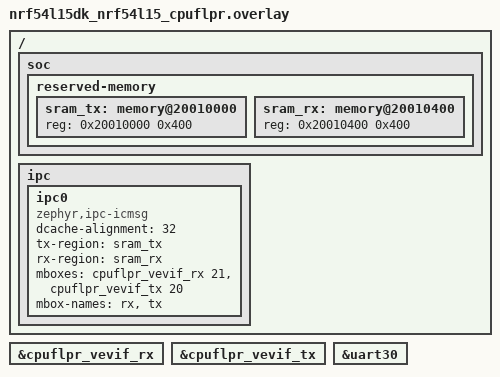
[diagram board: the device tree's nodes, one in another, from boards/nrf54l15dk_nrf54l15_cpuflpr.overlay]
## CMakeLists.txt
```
#
# Copyright (c) 2024 Nordic Semiconductor ASA
#
# SPDX-License-Identifier: LicenseRef-Nordic-5-Clause
#

cmake_minimum_required(VERSION 3.20.0)

find_package(Zephyr REQUIRED HINTS $ENV{ZEPHYR_BASE})
project(remote_icmsg)

target_sources(app PRIVATE src/main.c)

# CMSIS FFT Q15 Simplified
target_sources(app PRIVATE
    src/rfft_init_q15.c
    src/rfft_q15.c
    src/cfft_q15.c
    src/cfft_radix4_q15.c
    src/bit_reversal.c
    src/twiddle_tables.c
    src/fft_utils.c
)

# Ensure twiddle factor tables are placed in Flash (read-only)
# This is handled automatically by the linker for const data

# Dead code elimination
target_link_options(app PRIVATE
    -Wl,--gc-sections
)
```

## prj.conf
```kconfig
# Copyright (c) 2024 Nordic Semiconductor ASA
# SPDX-License-Identifier: LicenseRef-Nordic-5-Clause

CONFIG_PRINTK=y

CONFIG_LOG=y
CONFIG_LOG_PROCESS_THREAD_PRIORITY=-15
CONFIG_LOG_PROCESS_THREAD_CUSTOM_PRIORITY=y

CONFIG_HEAP_MEM_POOL_SIZE=1024

# Disable IPC Service - using simple ping-pong buffer instead
# CONFIG_IPC_SERVICE=y
# CONFIG_IPC_SERVICE_LOG_LEVEL_INF=y

# BELLBOARD (MBOX) for inter-core interrupts
CONFIG_MBOX=y
CONFIG_PM=n

# Enable XIP mode - execute code directly from Flash
CONFIG_XIP=y
```

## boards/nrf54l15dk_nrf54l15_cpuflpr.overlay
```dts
/*
 * FLPR IPC configuration for XIP memory layout
 * Shared memory region: 160KB (0x20010000-0x20038000)
 * TX/RX swapped from M33 perspective for bidirectional communication
 */

/ {
	soc {
		reserved-memory {
			#address-cells = <1>;
			#size-cells = <1>;

			// TX buffer: 1KB at 0x20010000 (M33's RX)
			sram_tx: memory@20010000 {
				reg = <0x20010000 0x400>;  // 1KB
			};

			// RX buffer: 1KB at 0x20010400 (M33's TX)
			sram_rx: memory@20010400 {
				reg = <0x20010400 0x400>;  // 1KB
			};
		};
	};

	ipc {
		ipc0: ipc0 {
			compatible = "zephyr,ipc-icmsg";
			dcache-alignment = <32>;
			tx-region = <&sram_tx>;
			rx-region = <&sram_rx>;
			mboxes = <&cpuflpr_vevif_rx 21>, <&cpuflpr_vevif_tx 20>;
			mbox-names = "rx", "tx";
			status = "okay";
		};
	};
};

&cpuflpr_vevif_rx {
	status = "okay";
};

&cpuflpr_vevif_tx {
	status = "okay";
};

&uart30 {
	/delete-property/ hw-flow-control;
};
```

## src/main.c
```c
/*
 * Copyright (c) 2025 Nordic Semiconductor ASA
 *
 * SPDX-License-Identifier: LicenseRef-Nordic-5-Clause
 *
 * Simple BELLBOARD Interrupt Test - FLPR Side
 * 
 * This test validates basic BELLBOARD interrupt functionality:
 * - FLPR sends interrupts to M33
 * - FLPR receives interrupts from M33
 * - Shared memory communication works
 */

#include <zephyr/kernel.h>
#include <zephyr/device.h>
#include <zephyr/drivers/mbox.h>
#include <zephyr/logging/log.h>
#include "ipc_pingpong.h"

LOG_MODULE_REGISTER(flpr_bellboard_test, LOG_LEVEL_INF);

/* Control block structure in shared memory */
struct control_block {
	volatile uint32_t flpr_counter;
	volatile uint32_t m33_counter;
	volatile uint32_t flpr_to_m33_count;
	volatile uint32_t m33_to_flpr_count;
};

static struct control_block *ctrl = (struct control_block *)CONTROL_BLOCK_ADDR;

/* Track last used buffer for round-robin selection */
static uint8_t last_buffer_used = 1;  /* Start with 1 so first acquisition tries buffer 0 */

/* MBOX device for BELLBOARD */
static const struct device *mbox_dev;
static const struct device *mbox_tx_dev;

/**
 * Notify M33 core via VEVIF interrupt
 * 
 * This function:
 * - Executes a memory barrier to ensure all writes are visible
 * - Triggers a VEVIF interrupt to M33 (channel 20)
 * - Handles errors from mbox_send
 * 
 * Requirements: 4.4, 7.1
 * 
 * @return BUFFER_OK on success, BUFFER_ERR_INVALID on failure
 */
static int vevif_notify_m33(void)
{
	int ret;
	
	/* Execute memory barrier before VEVIF trigger to ensure data visibility */
	MEMORY_BARRIER_FULL();
	
	/* Trigger VEVIF interrupt to M33 */
	ret = mbox_send_dt(&(struct mbox_dt_spec){
		.dev = mbox_tx_dev,
		.channel_id = 20
	}, NULL);
	
	if (ret < 0) {
		LOG_ERR("Failed to notify M33: %d", ret);
		return BUFFER_ERR_INVALID;
	}
	
	return BUFFER_OK;
}

/**
 * Acquire next available buffer for writing (FLPR write path)
 * 
 * This function:
 * - Searches for next IDLE buffer in round-robin order
 * - Uses atomic CAS to transition IDLE → WRITING
 * - Implements timeout using k_uptime_get() and polling
 * - Detects overrun when both buffers are not IDLE
 * - Increments overrun counter on overrun detection
 * - Returns buffer handle with pointer to data region
 * 
 * Requirements: 3.1, 3.2, 3.3, 6.1, 6.2, 6.3
 * 
 * @param handle Pointer to buffer_handle_t to populate
 * @param timeout_ms Timeout in milliseconds (0 = non-blocking)
 * @return BUFFER_OK on success, BUFFER_ERR_TIMEOUT on timeout, BUFFER_ERR_INVALID on invalid params
 */
int buffer_acquire_for_write(buffer_handle_t *handle, uint32_t timeout_ms)
{
	uint64_t start_time;
	uint64_t current_time;
	bool overrun_detected = false;
	
	/* Validate parameters */
	if (handle == NULL) {
		LOG_ERR("Invalid handle parameter");
		return BUFFER_ERR_INVALID;
	}
	
	/* Record start time for timeout */
	start_time = k_uptime_get();
	
	/* Try to acquire a buffer with timeout */
	while (1) {
		/* Try next buffer in round-robin order */
		uint8_t buffer_id = (last_buffer_used + 1) % 2;
		buffer_state_t current_state = buffer_get_state(buffer_id);
		
		if (current_state == BUFFER_STATE_IDLE) {
			/* Try to atomically transition IDLE → WRITING */
			if (atomic_cas_state(&CONTROL_BLOCK->buffer_states[buffer_id],
			                     BUFFER_STATE_IDLE,
			                     BUFFER_STATE_WRITING)) {
				/* Successfully acquired buffer */
				handle->id = buffer_id;
				handle->data = (void *)(buffer_id == 0 ? BUFFER_0_ADDR : BUFFER_1_ADDR);
				handle->size = BUFFER_SIZE;
				handle->state = &CONTROL_BLOCK->buffer_states[buffer_id];
				
				/* Update last used buffer for round-robin */
				last_buffer_used = buffer_id;
				
				LOG_DBG("Acquired buffer %d for writing", buffer_id);
				return BUFFER_OK;
			}
			/* CAS failed, another core may have acquired it, continue trying */
		}
		
		/* Check if both buffers are not IDLE (overrun condition) */
		buffer_state_t state0 = buffer_get_state(0);
		buffer_state_t state1 = buffer_get_state(1);
		
		if (state0 != BUFFER_STATE_IDLE && state1 != BUFFER_STATE_IDLE) {
			/* Overrun detected - both buffers are occupied */
			if (!overrun_detected) {
				/* Increment overrun counter only once per acquisition attempt */
				atomic_inc((atomic_t *)&CONTROL_BLOCK->overrun_count);
				overrun_detected = true;
				LOG_WRN("Buffer overrun detected (count: %d)", CONTROL_BLOCK->overrun_count);
			}
		}
		
		/* Check timeout */
		current_time = k_uptime_get();
		if ((current_time - start_time) >= timeout_ms) {
			LOG_WRN("Buffer acquisition timeout after %u ms", timeout_ms);
			atomic_inc((atomic_t *)&CONTROL_BLOCK->timeout_count);
			return BUFFER_ERR_TIMEOUT;
		}
		
		/* Small delay before retry to avoid busy-waiting */
		k_usleep(100);
	}
	
	/* Should never reach here */
	return BUFFER_ERR_INVALID;
}

/**
 * Commit written buffer and notify M33 (FLPR write path)
 * 
 * This function:
 * - Uses atomic CAS to transition WRITING → READY
 * - Executes memory barrier before notification
 * - Calls vevif_notify_m33() to trigger interrupt
 * - Increments write counter for the buffer
 * - Records timestamp using k_uptime_get()
 * 
 * Requirements: 3.4, 4.1, 7.1, 10.1, 10.2
 * 
 * @param handle Pointer to buffer_handle_t for the buffer to commit
 * @return BUFFER_OK on success, BUFFER_ERR_INVALID on invalid params, BUFFER_ERR_STATE on wrong state
 */
int buffer_commit(buffer_handle_t *handle)
{
	int ret;
	
	/* Validate parameters */
	if (handle == NULL) {
		LOG_ERR("Invalid handle parameter");
		return BUFFER_ERR_INVALID;
	}
	
	if (handle->id > 1) {
		LOG_ERR("Invalid buffer ID: %d", handle->id);
		return BUFFER_ERR_INVALID;
	}
	
	/* Try to atomically transition WRITING → READY */
	if (!atomic_cas_state(&CONTROL_BLOCK->buffer_states[handle->id],
	                      BUFFER_STATE_WRITING,
	                      BUFFER_STATE_READY)) {
		/* State transition failed - buffer is not in WRITING state */
		buffer_state_t current_state = buffer_get_state(handle->id);
		LOG_ERR("Buffer %d commit failed: expected WRITING, got %d", 
		        handle->id, current_state);
		return BUFFER_ERR_STATE;
	}
	
	/* Increment write counter for this buffer */
	atomic_inc((atomic_t *)&CONTROL_BLOCK->write_count[handle->id]);
	
	/* Record timestamp */
	uint64_t timestamp = k_uptime_get();
	CONTROL_BLOCK->last_write_ts[handle->id] = timestamp;
	
	/* Execute memory barrier before notification to ensure data visibility */
	MEMORY_BARRIER_FULL();
	
	/* Notify M33 that buffer is ready */
	ret = vevif_notify_m33();
	if (ret != BUFFER_OK) {
		LOG_ERR("Failed to notify M33 after commit: %d", ret);
		/* Note: Buffer is already in READY state, so M33 can still process it
		 * even if notification failed. This is a non-fatal error. */
	}
	
	LOG_DBG("Committed buffer %d (write count: %d, timestamp: %llu)",
	        handle->id, CONTROL_BLOCK->write_count[handle->id], timestamp);
	
	return BUFFER_OK;
}

/* Callback for BELLBOARD interrupt from M33 */
static void mbox_callback(const struct device *dev, uint32_t channel,
			  void *user_data, struct mbox_msg *msg)
{
	ARG_UNUSED(dev);
	ARG_UNUSED(user_data);
	ARG_UNUSED(msg);

	/* Increment interrupt counter */
	ctrl->m33_to_flpr_count++;

	LOG_INF("FLPR: Received interrupt #%d from M33 (M33 counter: %d)",
		ctrl->m33_to_flpr_count, ctrl->m33_counter);
}

int main(void)
{
	int ret;

	LOG_INF("=== FLPR VEVIF Interrupt Test ===");
	LOG_INF("Shared memory base: 0x%08X", (uint32_t)SHARED_MEM_BASE);
	LOG_INF("Control block: 0x%08X", (uint32_t)CONTROL_BLOCK_ADDR);

	/* Get MBOX device (VEVIF RX/TX) */
	mbox_dev = DEVICE_DT_GET(DT_NODELABEL(cpuflpr_vevif_rx));
	if (!device_is_ready(mbox_dev)) {
		LOG_ERR("MBOX RX device not ready");
		return -ENODEV;
	}

	LOG_INF("MBOX RX device ready");

	/* Get TX device */
	mbox_tx_dev = DEVICE_DT_GET(DT_NODELABEL(cpuflpr_vevif_tx));
	if (!device_is_ready(mbox_tx_dev)) {
		LOG_ERR("MBOX TX device not ready");
		return -ENODEV;
	}

	LOG_INF("MBOX TX device ready");

	/* Configure RX channel (receive from M33) - Channel 21 */
	ret = mbox_set_enabled_dt(&(struct mbox_dt_spec){
		.dev = mbox_dev,
		.channel_id = 21
	}, true);
	if (ret < 0) {
		LOG_ERR("Failed to enable RX channel: %d", ret);
		return ret;
	}

	/* Register callback for interrupts from M33 */
	ret = mbox_register_callback_dt(&(struct mbox_dt_spec){
		.dev = mbox_dev,
		.channel_id = 21
	}, mbox_callback, NULL);
	if (ret < 0) {
		LOG_ERR("Failed to register callback: %d", ret);
		return ret;
	}

	LOG_INF("RX channel configured (Channel 21: M33 -> FLPR)");
	LOG_INF("TX channel configured (Channel 20: FLPR -> M33)");
	LOG_INF("Starting ping-pong buffer test loop...");

	/* Statistics tracking */
	uint32_t iteration = 0;
	uint32_t last_stats_time = k_uptime_get_32();

	/* Main loop: acquire buffer, write data, commit, repeat */
	while (1) {
		buffer_handle_t buf;
		
		/* Acquire next available buffer for writing (1 second timeout) */
		ret = buffer_acquire_for_write(&buf, 1000);
		
		if (ret == BUFFER_ERR_TIMEOUT) {
			LOG_ERR("Failed to acquire buffer: timeout");
			/* Handle timeout - continue trying */
			k_msleep(100);
			continue;
		} else if (ret != BUFFER_OK) {
			LOG_ERR("Failed to acquire buffer: %d", ret);
			/* Handle other errors */
			k_msleep(100);
			continue;
		}
		
		/* Successfully acquired buffer - write test data pattern */
		uint32_t *data = (uint32_t *)buf.data;
		uint32_t pattern_base = iteration;
		
		/* Fill buffer with test pattern: incrementing values based on iteration */
		for (size_t i = 0; i < (buf.size / sizeof(uint32_t)); i++) {
			data[i] = pattern_base + i;
		}
		
		LOG_DBG("FLPR: Wrote test pattern to buffer %d (base: 0x%08X)", 
		        buf.id, pattern_base);
		
		/* Commit buffer and notify M33 */
		ret = buffer_commit(&buf);
		
		if (ret != BUFFER_OK) {
			LOG_ERR("Failed to commit buffer %d: %d", buf.id, ret);
			/* Buffer is in inconsistent state - this is a critical error */
			/* In production, might want to reset the buffer state */
		} else {
			LOG_INF("FLPR: Committed buffer %d (iteration %u)", buf.id, iteration);
		}
		
		/* Increment iteration counter */
		iteration++;
		
		/* Log statistics periodically (every 5 seconds) */
		uint32_t current_time = k_uptime_get_32();
		if ((current_time - last_stats_time) >= 5000) {
			LOG_INF("=== FLPR Statistics ===");
			LOG_INF("  Iterations: %u", iteration);
			LOG_INF("  Buffer 0 writes: %u", CONTROL_BLOCK->write_count[0]);
			LOG_INF("  Buffer 1 writes: %u", CONTROL_BLOCK->write_count[1]);
			LOG_INF("  Overruns: %u", CONTROL_BLOCK->overrun_count);
			LOG_INF("  Timeouts: %u", CONTROL_BLOCK->timeout_count);
			LOG_INF("  Legacy FLPR->M33: %u, M33->FLPR: %u",
			        ctrl->flpr_to_m33_count, ctrl->m33_to_flpr_count);
			
			last_stats_time = current_time;
		}
		
		/* Small delay between writes to simulate realistic data production rate */
		k_msleep(500);
	}

	return 0;
}
```

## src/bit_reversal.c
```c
/* ----------------------------------------------------------------------
 * Project:      CMSIS DSP Library - Simplified Q15 FFT
 * Title:        bit_reversal.c
 * Description:  Bit reversal functions for FFT
 *
 * Target Processor: ARM Cortex-M33
 * -------------------------------------------------------------------- */
/*
 * Copyright (C) 2010-2021 ARM Limited or its affiliates. All rights reserved.
 *
 * SPDX-License-Identifier: Apache-2.0
 */

#include "rfft_q15_simplified.h"

/**
 * @brief In-place Q15 bit reversal function.
 * @param[in,out] pSrc        points to in-place Q15 data buffer
 * @param[in]     bitRevLen   bit reversal table length
 * @param[in]     pBitRevTable points to bit reversal table
 */
void arm_bitreversal_16(
        uint16_t * pSrc,
  const uint16_t bitRevLen,
  const uint16_t * pBitRevTable)
{
    uint16_t a, b, tmp;
    uint32_t i;

    for (i = 0; i < bitRevLen; )
    {
        a = pBitRevTable[i    ] >> 2;
        b = pBitRevTable[i + 1] >> 2;

        /* Swap real parts */
        tmp = pSrc[a];
        pSrc[a] = pSrc[b];
        pSrc[b] = tmp;

        /* Swap imaginary parts */
        tmp = pSrc[a+1];
        pSrc[a+1] = pSrc[b+1];
        pSrc[b+1] = tmp;

        i += 2;
    }
}
```

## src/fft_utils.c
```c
/* ----------------------------------------------------------------------
 * Project:      FFT Utility Functions
 * Title:        fft_utils.c
 * Description:  High-level FFT utility functions implementation
 *
 * Target Processor: nRF54L15 FLPR (RISC-V)
 * -------------------------------------------------------------------- */

#include "fft_utils.h"
#include <string.h>

/* Static buffers for FFT processing */
#ifdef ENABLE_FFT_8K
static q15_t fft_input_buffer[8192];   /* Max FFT size: 8192 */
static q15_t fft_output_buffer[16384]; /* 2 * max FFT size for complex output */
#else
static q15_t fft_input_buffer[4096];   /* Max FFT size: 4096 */
static q15_t fft_output_buffer[8192];  /* 2 * max FFT size for complex output */
#endif

/* Structure for bin sorting */
typedef struct {
    uint16_t bin_index;
    uint32_t magnitude_squared;
} bin_magnitude_t;

/**
 * @brief Find the top N frequency bins with highest magnitude from FFT
 */
rfft_status_t find_fft_top_bins(
    const q15_t *input_signal,
    uint16_t input_length,
    uint16_t fft_size,
    uint16_t *output_bin_indices,
    uint16_t num_top_bins
)
{
    /* Input validation */
    if (input_signal == NULL || output_bin_indices == NULL) {
        return RFFT_ERROR_NULL_POINTER;
    }
    
    if (input_length != fft_size) {
        return RFFT_ERROR_INVALID_SIZE;
    }
    
    if (fft_size != 4096 && fft_size != 8192) {
        return RFFT_ERROR_INVALID_SIZE;
    }
    
#ifndef ENABLE_FFT_8K
    if (fft_size == 8192) {
        return RFFT_ERROR_INVALID_SIZE;  /* 8192 not enabled */
    }
#endif
    
    if (num_top_bins == 0 || num_top_bins > (fft_size / 2)) {
        return RFFT_ERROR_INVALID_SIZE;
    }
    
    /* Initialize RFFT instance */
    arm_rfft_instance_q15 rfft_instance;
    rfft_status_t status;
    
    if (fft_size == 4096) {
        status = rfft_q15_init_4096(&rfft_instance);
    } 
#ifdef ENABLE_FFT_8K
    else {
        status = rfft_q15_init_8192(&rfft_instance);
    }
#else
    else {
        return RFFT_ERROR_INVALID_SIZE;
    }
#endif
    
    if (status != RFFT_SUCCESS) {
        return status;
    }
    
    /* Copy input to working buffer */
    memcpy(fft_input_buffer, input_signal, fft_size * sizeof(q15_t));
    
    /* Perform RFFT */
    arm_rfft_q15(&rfft_instance, fft_input_buffer, fft_output_buffer);
    
    /* Allocate array for top bins (on stack) */
    bin_magnitude_t top_bins[num_top_bins];
    
    /* Initialize top_bins array */
    for (uint16_t i = 0; i < num_top_bins; i++) {
        top_bins[i].bin_index = 0;
        top_bins[i].magnitude_squared = 0;
    }
    
    /* Calculate magnitude² for all bins and find top N */
    /* Note: Skip DC bin (bin 0) */
    uint16_t num_bins = fft_size / 2 + 1;
    
    for (uint16_t bin = 1; bin < num_bins; bin++) {
        /* Get real and imaginary parts (13.3 format for 4096, 14.2 for 8192) */
        int16_t real = fft_output_buffer[bin * 2];
        int16_t imag = fft_output_buffer[bin * 2 + 1];
        
        /* Calculate magnitude² (using raw values to avoid overflow) */
        uint32_t mag_sq = (uint32_t)((int32_t)real * real + (int32_t)imag * imag);
        
        /* Check if this bin should be in top N */
        for (uint16_t i = 0; i < num_top_bins; i++) {
            if (mag_sq > top_bins[i].magnitude_squared) {
                /* Insert at position i, shift others down */
                for (uint16_t j = num_top_bins - 1; j > i; j--) {
                    top_bins[j] = top_bins[j - 1];
                }
                top_bins[i].bin_index = bin;
                top_bins[i].magnitude_squared = mag_sq;
                break;
            }
        }
    }
    
    /* Copy bin indices to output array */
    for (uint16_t i = 0; i < num_top_bins; i++) {
        output_bin_indices[i] = top_bins[i].bin_index;
    }
    
    return RFFT_SUCCESS;
}
```

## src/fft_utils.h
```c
/* ----------------------------------------------------------------------
 * Project:      FFT Utility Functions
 * Title:        fft_utils.h
 * Description:  High-level FFT utility functions for signal processing
 *
 * Target Processor: nRF54L15 FLPR (RISC-V)
 * -------------------------------------------------------------------- */

#ifndef FFT_UTILS_H
#define FFT_UTILS_H

#include "rfft_q15_simplified.h"

#ifdef __cplusplus
extern "C" {
#endif

/**
 * @brief Find the top N frequency bins with highest magnitude from FFT
 * 
 * @param[in]  input_signal      Pointer to input signal buffer (Q15 format)
 * @param[in]  input_length      Length of input signal (must equal fft_size)
 * @param[in]  fft_size          FFT size (4096 or 8192)
 * @param[out] output_bin_indices Array to store sorted bin indices (size >= num_top_bins)
 * @param[in]  num_top_bins      Number of top bins to find (e.g., 20)
 * 
 * @return rfft_status_t
 *         - RFFT_SUCCESS: Operation successful
 *         - RFFT_ERROR_NULL_POINTER: NULL pointer provided
 *         - RFFT_ERROR_INVALID_SIZE: Invalid FFT size or input length
 * 
 * @note This function:
 *       - Performs RFFT on the input signal
 *       - Calculates magnitude² for all frequency bins
 *       - Sorts bins by magnitude and returns top N bin indices
 *       - Skips DC bin (bin 0) in the results
 *       - Uses static buffers internally (not thread-safe)
 * 
 * @example
 *   q15_t signal[4096];
 *   uint16_t top_bins[20];
 *   
 *   // Fill signal with ADC data
 *   for (int i = 0; i < 4096; i++) {
 *       signal[i] = adc_to_q15(adc_read());
 *   }
 *   
 *   // Find top 20 frequency bins
 *   rfft_status_t status = find_fft_top_bins(
 *       signal, 4096, 4096, top_bins, 20
 *   );
 *   
 *   if (status == RFFT_SUCCESS) {
 *       // top_bins[0] contains the bin with highest magnitude
 *       // top_bins[1] contains the bin with 2nd highest magnitude
 *       // ...
 *   }
 */
rfft_status_t find_fft_top_bins(
    const q15_t *input_signal,
    uint16_t input_length,
    uint16_t fft_size,
    uint16_t *output_bin_indices,
    uint16_t num_top_bins
);

#ifdef __cplusplus
}
#endif

#endif /* FFT_UTILS_H */
```

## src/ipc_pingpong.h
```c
../../src/ipc_pingpong.h
```

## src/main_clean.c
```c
/*
 * Copyright (c) 2022 Nordic Semiconductor ASA
 *
 * SPDX-License-Identifier: LicenseRef-Nordic-5-Clause
 */

#include <zephyr/kernel.h>
#include <zephyr/device.h>
#include <string.h>

#include <zephyr/logging/log.h>

#include <zephyr/ipc/ipc_service.h>

/* Uncomment to use FFT utilities */
/* #include "rfft_q15_simplified.h" */
/* #include "fft_utils.h" */

#ifdef CONFIG_TEST_EXTRA_STACK_SIZE
#define STACKSIZE	(1024 + CONFIG_TEST_EXTRA_STACK_SIZE)
#else
#define STACKSIZE	(1024)
#endif

K_THREAD_STACK_DEFINE(ipc0_stack, STACKSIZE);

LOG_MODULE_REGISTER(host, LOG_LEVEL_INF);

struct payload {
	unsigned long cnt;
	unsigned long size;
	uint8_t data[CONFIG_APP_IPC_SERVICE_MESSAGE_LEN - sizeof(unsigned long) * 2];
};

static struct payload payload_buffer;
static struct payload *p_payload = &payload_buffer;

static K_SEM_DEFINE(bound_sem, 0, 1);

static void ep_bound(void *priv)
{
	k_sem_give(&bound_sem);
}

static void ep_recv(const void *data, size_t len, void *priv)
{
	uint8_t received_val = *((uint8_t *)data);
	static uint8_t expected_val;

	if ((received_val != expected_val) || (len != CONFIG_APP_IPC_SERVICE_MESSAGE_LEN)) {
		printk("Unexpected message received_val: %d , expected_val: %d\n",
			received_val,
			expected_val);
	}

	expected_val++;
}

static struct ipc_ept_cfg ep_cfg = {
	.name = "ep0",
	.cb = {
		.bound    = ep_bound,
		.received = ep_recv,
	},
};

static void check_task(void *arg1, void *arg2, void *arg3)
{
	ARG_UNUSED(arg1);
	ARG_UNUSED(arg2);
	ARG_UNUSED(arg3);

	unsigned long last_cnt = p_payload->cnt;
	unsigned long delta;

	while (1) {
		k_sleep(K_MSEC(1000));

		delta = p_payload->cnt - last_cnt;

		printk("Remote Δpkt: %ld (%ld B/pkt) | throughput: %ld bit/s\n",
			delta, p_payload->size, delta * CONFIG_APP_IPC_SERVICE_MESSAGE_LEN * 8);

		last_cnt = p_payload->cnt;
	}
}

K_THREAD_DEFINE(thread_check_id, STACKSIZE, check_task, NULL, NULL, NULL,
		K_PRIO_COOP(1), 0, -1);

int main(void)
{
	const struct device *ipc0_instance;
	struct ipc_ept ep;
	int ret;

	memset(p_payload->data, 0xA5, sizeof(p_payload->data));

	p_payload->size = CONFIG_APP_IPC_SERVICE_MESSAGE_LEN;
	p_payload->cnt = 0;

	printk("Remote IPC-service %s demo started\n", CONFIG_BOARD_TARGET);

	ipc0_instance = DEVICE_DT_GET(DT_NODELABEL(ipc0));

#if defined(CONFIG_IPC_SERVICE_BACKEND_ICBMSG)
	/* Wait a bit for the remote core to boot. */
	k_msleep(100);
#endif

	ret = ipc_service_open_instance(ipc0_instance);
	if ((ret < 0) && (ret != -EALREADY)) {
		LOG_INF("ipc_service_open_instance() failure (%d)", ret);
		return ret;
	}

	ret = ipc_service_register_endpoint(ipc0_instance, &ep, &ep_cfg);
	if (ret < 0) {
		printf("ipc_service_register_endpoint() failure (%d)", ret);
		return ret;
	}

	k_sem_take(&bound_sem, K_FOREVER);
	k_thread_start(thread_check_id);

	while (true) {
		ret = ipc_service_send(&ep, p_payload, CONFIG_APP_IPC_SERVICE_MESSAGE_LEN);
		if (ret == -ENOMEM) {
			/* No space in the buffer. Retry. */
			continue;
		} else if (ret < 0) {
			printk("send_message(%ld) failed with ret %d\n", p_payload->cnt, ret);
			break;
		}

		p_payload->cnt++;

		/* Quasi minimal busy wait time which allows to continuously send
		 * data without -ENOMEM error code. The purpose is to test max
		 * throughput. Determined experimentally.
		 */
		if (CONFIG_APP_IPC_SERVICE_SEND_INTERVAL < 1000) {
			k_busy_wait(CONFIG_APP_IPC_SERVICE_SEND_INTERVAL);
		} else {
			k_msleep(CONFIG_APP_IPC_SERVICE_SEND_INTERVAL/1000);
		}
	}

	return 0;
}
```

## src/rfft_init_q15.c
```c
/* ----------------------------------------------------------------------
 * Project:      CMSIS DSP Library - Simplified Q15 RFFT
 * Title:        rfft_init_q15.c
 * Description:  Initialization functions for Q15 RFFT
 *
 * Target Processor: ARM Cortex-M33
 * -------------------------------------------------------------------- */
/*
 * Copyright (C) 2010-2021 ARM Limited or its affiliates. All rights reserved.
 *
 * SPDX-License-Identifier: Apache-2.0
 */

#include "rfft_q15_simplified.h"
#include <stddef.h>

/* Static CFFT instances for internal use */
static const arm_cfft_instance_q15 arm_cfft_sR_q15_len2048 = {
    2048,
    twiddleCoef_2048_q15,
    armBitRevIndexTable_fixed_2048,
    ARMBITREVINDEXTABLE_FIXED_2048_TABLE_LENGTH
};

#ifdef ENABLE_FFT_8K
static const arm_cfft_instance_q15 arm_cfft_sR_q15_len4096 = {
    4096,
    twiddleCoef_4096_q15,
    armBitRevIndexTable_fixed_4096,
    ARMBITREVINDEXTABLE_FIXED_4096_TABLE_LENGTH
};
#endif

/**
 * @brief Initialize RFFT instance for 4096-point FFT.
 * @param[out] S  Pointer to RFFT instance structure
 * @return Status code
 */
rfft_status_t rfft_q15_init_4096(arm_rfft_instance_q15 *S)
{
    if (S == NULL) {
        return RFFT_ERROR_NULL_POINTER;
    }

    /* Initialize the Real FFT length */
    S->fftLenReal = 4096U;

    /* Initialize the Twiddle coefficient modifier */
    S->twidCoefRModifier = 2U;

    /* Initialize the Flag for selection of RFFT or RIFFT */
    S->ifftFlagR = 0U;

    /* Initialize the Flag for calculation Bit reversal or not */
    S->bitReverseFlagR = 1U;

    /* Initialize the Twiddle coefficient A pointer */
    S->pTwiddleAReal = (q15_t *) realCoefAQ15;

    /* Initialize the Twiddle coefficient B pointer */
    S->pTwiddleBReal = (q15_t *) realCoefBQ15;

    /* Initialize the CFFT/CIFFT instance pointer */
    S->pCfft = &arm_cfft_sR_q15_len2048;

    return RFFT_SUCCESS;
}

#ifdef ENABLE_FFT_8K
/**
 * @brief Initialize RFFT instance for 8192-point FFT.
 * @param[out] S  Pointer to RFFT instance structure
 * @return Status code
 */
rfft_status_t rfft_q15_init_8192(arm_rfft_instance_q15 *S)
{
    if (S == NULL) {
        return RFFT_ERROR_NULL_POINTER;
    }

    /* Initialize the Real FFT length */
    S->fftLenReal = 8192U;

    /* Initialize the Twiddle coefficient modifier */
    S->twidCoefRModifier = 1U;

    /* Initialize the Flag for selection of RFFT or RIFFT */
    S->ifftFlagR = 0U;

    /* Initialize the Flag for calculation Bit reversal or not */
    S->bitReverseFlagR = 1U;

    /* Initialize the Twiddle coefficient A pointer */
    S->pTwiddleAReal = (q15_t *) realCoefAQ15;

    /* Initialize the Twiddle coefficient B pointer */
    S->pTwiddleBReal = (q15_t *) realCoefBQ15;

    /* Initialize the CFFT/CIFFT instance pointer */
    S->pCfft = &arm_cfft_sR_q15_len4096;

    return RFFT_SUCCESS;
}
#endif /* ENABLE_FFT_8K */
```

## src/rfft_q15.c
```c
/* ----------------------------------------------------------------------
 * Project:      CMSIS DSP Library - Simplified Q15 RFFT
 * Title:        rfft_q15.c
 * Description:  Simplified RFFT Q15 process function for ARM Cortex-M33
 *
 * Target Processor: ARM Cortex-M33
 * -------------------------------------------------------------------- */
/*
 * Copyright (C) 2010-2021 ARM Limited or its affiliates. All rights reserved.
 *
 * SPDX-License-Identifier: Apache-2.0
 */

#include "rfft_q15_simplified.h"
#include <stddef.h>

/* External CFFT function declaration */
extern void arm_cfft_q15(
    const arm_cfft_instance_q15 * S,
    q15_t * p1,
    uint8_t ifftFlag,
    uint8_t bitReverseFlag);

/* Internal split function for RFFT */
static void arm_split_rfft_q15(
        q15_t * pSrc,
        uint32_t fftLen,
  const q15_t * pATable,
  const q15_t * pBTable,
        q15_t * pDst,
        uint32_t modifier);

/* Internal split function for RIFFT */
static void arm_split_rifft_q15(
        q15_t * pSrc,
        uint32_t fftLen,
  const q15_t * pATable,
  const q15_t * pBTable,
        q15_t * pDst,
        uint32_t modifier);

/**
 * @brief Processing function for the Q15 RFFT.
 * @param[in]     S     points to an instance of the Q15 RFFT structure
 * @param[in]     pSrc  points to input buffer (modified by this function)
 * @param[out]    pDst  points to output buffer
 */
void arm_rfft_q15(
  const arm_rfft_instance_q15 * S,
        q15_t * pSrc,
        q15_t * pDst)
{
    const arm_cfft_instance_q15 *S_CFFT = S->pCfft;
    uint32_t L2 = S->fftLenReal >> 1U;

    /* Calculation of RIFFT of input */
    if (S->ifftFlagR == 1U)
    {
        /* Real IFFT core process */
        arm_split_rifft_q15(pSrc, L2, S->pTwiddleAReal, S->pTwiddleBReal, pDst, S->twidCoefRModifier);

        /* Complex IFFT process */
        arm_cfft_q15(S_CFFT, pDst, S->ifftFlagR, S->bitReverseFlagR);

        /* Shift output by 1 for IFFT */
        for (uint32_t i = 0; i < S->fftLenReal; i++)
        {
            pDst[i] = pDst[i] << 1;
        }
    }
    else
    {
        /* Calculation of RFFT of input */

        /* Complex FFT process */
        arm_cfft_q15(S_CFFT, pSrc, S->ifftFlagR, S->bitReverseFlagR);

        /* Real FFT core process */
        arm_split_rfft_q15(pSrc, L2, S->pTwiddleAReal, S->pTwiddleBReal, pDst, S->twidCoefRModifier);
    }
}

/**
 * @brief Core Real FFT process
 * @param[in]     pSrc      points to input buffer
 * @param[in]     fftLen    length of FFT
 * @param[in]     pATable   points to twiddle Coef A buffer
 * @param[in]     pBTable   points to twiddle Coef B buffer
 * @param[out]    pDst      points to output buffer
 * @param[in]     modifier  twiddle coefficient modifier
 */
static void arm_split_rfft_q15(
        q15_t * pSrc,
        uint32_t fftLen,
  const q15_t * pATable,
  const q15_t * pBTable,
        q15_t * pDst,
        uint32_t modifier)
{       
    uint32_t i;
    q31_t outR, outI;
    const q15_t *pCoefA, *pCoefB;
    q15_t *pSrc1, *pSrc2;

#if defined (ARM_MATH_DSP)
    q15_t *pD1, *pD2;
#endif

    /* Init coefficient pointers */
    pCoefA = &pATable[modifier * 2];
    pCoefB = &pBTable[modifier * 2];

    pSrc1 = &pSrc[2];
    pSrc2 = &pSrc[(2U * fftLen) - 2U];

#if defined (ARM_MATH_DSP)

    i = 1U;
    pD1 = pDst + 2;
    pD2 = pDst + (4U * fftLen) - 2;

    for (i = fftLen - 1; i > 0; i--)
    {
        /*
          outR = (  pSrc[2 * i]             * pATable[2 * i]
                  - pSrc[2 * i + 1]         * pATable[2 * i + 1]
                  + pSrc[2 * n - 2 * i]     * pBTable[2 * i]
                  + pSrc[2 * n - 2 * i + 1] * pBTable[2 * i + 1]);

          outI = (  pIn[2 * i + 1]         * pATable[2 * i]
                  + pIn[2 * i]             * pATable[2 * i + 1]
                  + pIn[2 * n - 2 * i]     * pBTable[2 * i + 1]
                  - pIn[2 * n - 2 * i + 1] * pBTable[2 * i])
         */

#ifndef ARM_MATH_BIG_ENDIAN
        /* pSrc[2 * i] * pATable[2 * i] - pSrc[2 * i + 1] * pATable[2 * i + 1] */
        outR = __SMUSD(*((q31_t *)pSrc1), *((q31_t *)pCoefA));
#else
        /* -(pSrc[2 * i + 1] * pATable[2 * i + 1] - pSrc[2 * i] * pATable[2 * i]) */
        outR = -(__SMUSD(*((q31_t *)pSrc1), *((q31_t *)pCoefA)));
#endif

        /* pSrc[2 * n - 2 * i] * pBTable[2 * i] + pSrc[2 * n - 2 * i + 1] * pBTable[2 * i + 1]) */
        outR = __SMLAD(*((q31_t *)pSrc2), *((q31_t *)pCoefB), outR) >> 16U;

        /* pIn[2 * n - 2 * i] * pBTable[2 * i + 1] - pIn[2 * n - 2 * i + 1] * pBTable[2 * i] */
#ifndef ARM_MATH_BIG_ENDIAN
        outI = __SMUSDX(*((q31_t *)pSrc2), *((q31_t *)pCoefB));
        pSrc2 -= 2;
#else
        outI = __SMUSDX(*((q31_t *)pCoefB), *((q31_t *)pSrc2));
        pSrc2 -= 2;
#endif

        /* (pIn[2 * i + 1] * pATable[2 * i] + pIn[2 * i] * pATable[2 * i + 1] */
        outI = __SMLADX(*((q31_t *)pSrc1), *((q31_t *)pCoefA), outI);
        pSrc1 += 2;

        /* write output */
        *pD1++ = (q15_t) outR;
        *pD1++ = outI >> 16U;

        /* write complex conjugate output */
        pD2[0] = (q15_t) outR;
        pD2[1] = -(outI >> 16U);
        pD2 -= 2;

        /* update coefficient pointer */
        pCoefB = pCoefB + (2U * modifier);
        pCoefA = pCoefA + (2U * modifier);
    }

    pDst[2U * fftLen]      = (pSrc[0] - pSrc[1]) >> 1U;
    pDst[2U * fftLen + 1U] = 0;

    pDst[0] = (pSrc[0] + pSrc[1]) >> 1U;
    pDst[1] = 0;

#else

    i = 1U;

    while (i < fftLen)
    {
        /*
          outR = (  pSrc[2 * i]             * pATable[2 * i]
                  - pSrc[2 * i + 1]         * pATable[2 * i + 1]
                  + pSrc[2 * n - 2 * i]     * pBTable[2 * i]
                  + pSrc[2 * n - 2 * i + 1] * pBTable[2 * i + 1]);
        */

        outR = *pSrc1 * *pCoefA;
        outR = outR - (*(pSrc1 + 1) * *(pCoefA + 1));
        outR = outR + (*pSrc2 * *pCoefB);
        outR = (outR + (*(pSrc2 + 1) * *(pCoefB + 1))) >> 16;

        /*
          outI = (  pIn[2 * i + 1]         * pATable[2 * i]
                  + pIn[2 * i]             * pATable[2 * i + 1]
                  + pIn[2 * n - 2 * i]     * pBTable[2 * i + 1]
                  - pIn[2 * n - 2 * i + 1] * pBTable[2 * i]);
        */

        outI = *pSrc2 * *(pCoefB + 1);
        outI = outI - (*(pSrc2 + 1) * *pCoefB);
        outI = outI + (*(pSrc1 + 1) * *pCoefA);
        outI = outI + (*pSrc1 * *(pCoefA + 1));

        /* update input pointers */
        pSrc1 += 2U;
        pSrc2 -= 2U;

        /* write output */
        pDst[2U * i] = (q15_t) outR;
        pDst[2U * i + 1U] = outI >> 16U;

        /* write complex conjugate output */
        pDst[(4U * fftLen) - (2U * i)] = (q15_t) outR;
        pDst[((4U * fftLen) - (2U * i)) + 1U] = -(outI >> 16U);

        /* update coefficient pointer */
        pCoefB = pCoefB + (2U * modifier);
        pCoefA = pCoefA + (2U * modifier);

        i++;
    }

    pDst[2U * fftLen] = (pSrc[0] - pSrc[1]) >> 1;
    pDst[2U * fftLen + 1U] = 0;

    pDst[0] = (pSrc[0] + pSrc[1]) >> 1;
    pDst[1] = 0;

#endif /* #if defined (ARM_MATH_DSP) */
}

/**
 * @brief Core Real IFFT process
 * @param[in]     pSrc      points to input buffer
 * @param[in]     fftLen    length of FFT
 * @param[in]     pATable   points to twiddle Coef A buffer
 * @param[in]     pBTable   points to twiddle Coef B buffer
 * @param[out]    pDst      points to output buffer
 * @param[in]     modifier  twiddle coefficient modifier
 */
static void arm_split_rifft_q15(
        q15_t * pSrc,
        uint32_t fftLen,
  const q15_t * pATable,
  const q15_t * pBTable,
        q15_t * pDst,
        uint32_t modifier)
{
    uint32_t i;
    q31_t outR, outI;
    const q15_t *pCoefA, *pCoefB;
    q15_t *pSrc1, *pSrc2;
    q15_t *pDst1 = &pDst[0];

    pCoefA = &pATable[0];
    pCoefB = &pBTable[0];

    pSrc1 = &pSrc[0];
    pSrc2 = &pSrc[2 * fftLen];

    i = fftLen;
    while (i > 0U)
    {
        /*
          outR = (  pIn[2 * i]             * pATable[2 * i]
                  + pIn[2 * i + 1]         * pATable[2 * i + 1]
                  + pIn[2 * n - 2 * i]     * pBTable[2 * i]
                  - pIn[2 * n - 2 * i + 1] * pBTable[2 * i + 1]);

          outI = (  pIn[2 * i + 1]         * pATable[2 * i]
                  - pIn[2 * i]             * pATable[2 * i + 1]
                  - pIn[2 * n - 2 * i]     * pBTable[2 * i + 1]
                  - pIn[2 * n - 2 * i + 1] * pBTable[2 * i]);
         */

#if defined (ARM_MATH_DSP)

#ifndef ARM_MATH_BIG_ENDIAN
        /* pIn[2 * n - 2 * i] * pBTable[2 * i] - pIn[2 * n - 2 * i + 1] * pBTable[2 * i + 1]) */
        outR = __SMUSD(*((q31_t *)pSrc2), *((q31_t *)pCoefB));
#else
        /* -(-pIn[2 * n - 2 * i] * pBTable[2 * i] + pIn[2 * n - 2 * i + 1] * pBTable[2 * i + 1])) */
        outR = -(__SMUSD(*((q31_t *)pSrc2), *((q31_t *)pCoefB)));
#endif

        /* pIn[2 * i] * pATable[2 * i] + pIn[2 * i + 1] * pATable[2 * i + 1] + pIn[2 * n - 2 * i] * pBTable[2 * i] */
        outR = __SMLAD(*((q31_t *)pSrc1), *((q31_t *)pCoefA), outR) >> 16U;

        /* -pIn[2 * n - 2 * i] * pBTable[2 * i + 1] + pIn[2 * n - 2 * i + 1] * pBTable[2 * i] */
        outI = __SMUADX(*((q31_t *)pSrc2), *((q31_t *)pCoefB));
        pSrc2 -= 2;

        /* pIn[2 * i + 1] * pATable[2 * i] - pIn[2 * i] * pATable[2 * i + 1] */
#ifndef ARM_MATH_BIG_ENDIAN
        outI = __SMLSDX(*((q31_t *)pCoefA), *((q31_t *)pSrc1), -outI);
        pSrc1 += 2;
#else
        outI = __SMLSDX(*((q31_t *)pSrc1), *((q31_t *)pCoefA), -outI);
        pSrc1 += 2;
#endif

        /* write output */
#ifndef ARM_MATH_BIG_ENDIAN
        *((q31_t *)pDst1) = __PKHBT(outR, (outI >> 16U), 16);
        pDst1 += 2;
#else
        *((q31_t *)pDst1) = __PKHBT((outI >> 16U), outR, 16);
        pDst1 += 2;
#endif

#else  /* #if defined (ARM_MATH_DSP) */

        outR = *pSrc2 * *pCoefB;
        outR = outR - (*(pSrc2 + 1) * *(pCoefB + 1));
        outR = outR + (*pSrc1 * *pCoefA);
        outR = (outR + (*(pSrc1 + 1) * *(pCoefA + 1))) >> 16;

        outI = *(pSrc1 + 1) * *pCoefA;
        outI = outI - (*pSrc1 * *(pCoefA + 1));
        outI = outI - (*pSrc2 * *(pCoefB + 1));
        outI = outI - (*(pSrc2 + 1) * *(pCoefB));

        /* update input pointers */
        pSrc1 += 2U;
        pSrc2 -= 2U;

        /* write output */
        *pDst1++ = (q15_t) outR;
        *pDst1++ = (q15_t) (outI >> 16);

#endif /* #if defined (ARM_MATH_DSP) */

        /* update coefficient pointer */
        pCoefB = pCoefB + (2 * modifier);
        pCoefA = pCoefA + (2 * modifier);

        i--;
    }
}
```

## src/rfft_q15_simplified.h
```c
/* ----------------------------------------------------------------------
 * Project:      CMSIS DSP Library - Simplified Q15 RFFT
 * Title:        rfft_q15.h
 * Description:  Public header file for simplified Q15 RFFT implementation
 *
 * Target Processor: ARM Cortex-M33
 * -------------------------------------------------------------------- */
/*
 * Copyright (C) 2010-2021 ARM Limited or its affiliates. All rights reserved.
 *
 * SPDX-License-Identifier: Apache-2.0
 */

#ifndef RFFT_Q15_H
#define RFFT_Q15_H

#include <stdint.h>

#ifdef __cplusplus
extern "C" {
#endif

/* ========================================================================= */
/* Type Definitions                                                          */
/* ========================================================================= */

/**
 * @brief 16-bit fractional data type in 1.15 format.
 */
typedef int16_t q15_t;

/**
 * @brief 32-bit fractional data type in 1.31 format.
 */
typedef int32_t q31_t;

/**
 * @brief Complex number structure for Q15 format.
 */
typedef struct {
    q15_t real;  /**< Real part */
    q15_t imag;  /**< Imaginary part */
} complex_q15_t;

/**
 * @brief Error status codes.
 */
typedef enum {
    RFFT_SUCCESS = 0,              /**< No error */
    RFFT_ERROR_INVALID_SIZE = -1,  /**< Invalid FFT size */
    RFFT_ERROR_NULL_POINTER = -2   /**< Null pointer error */
} rfft_status_t;

/**
 * @brief Instance structure for the Q15 CFFT/CIFFT function.
 */
typedef struct {
    uint16_t fftLen;                   /**< length of the FFT. */
    const q15_t *pTwiddle;             /**< points to the Twiddle factor table. */
    const uint16_t *pBitRevTable;      /**< points to the bit reversal table. */
    uint16_t bitRevLength;             /**< bit reversal table length. */
} arm_cfft_instance_q15;

/**
 * @brief Instance structure for the Q15 RFFT/RIFFT function.
 */
typedef struct {
    uint32_t fftLenReal;                      /**< length of the real FFT. */
    uint8_t ifftFlagR;                        /**< flag that selects forward (ifftFlagR=0) or inverse (ifftFlagR=1) transform. */
    uint8_t bitReverseFlagR;                  /**< flag that enables (bitReverseFlagR=1) or disables (bitReverseFlagR=0) bit reversal of output. */
    uint32_t twidCoefRModifier;               /**< twiddle coefficient modifier that supports different size FFTs with the same twiddle factor table. */
    const q15_t *pTwiddleAReal;               /**< points to the real twiddle factor table. */
    const q15_t *pTwiddleBReal;               /**< points to the imag twiddle factor table. */
    const arm_cfft_instance_q15 *pCfft;       /**< points to the complex FFT instance. */
} arm_rfft_instance_q15;

/* ========================================================================= */
/* Public API Functions                                                      */
/* ========================================================================= */

/**
 * @brief Initialize RFFT instance for 4096-point FFT.
 * @param[out] S  Pointer to RFFT instance structure
 * @return Status code
 */
rfft_status_t rfft_q15_init_4096(arm_rfft_instance_q15 *S);

#ifdef ENABLE_FFT_8K
/**
 * @brief Initialize RFFT instance for 8192-point FFT.
 * @param[out] S  Pointer to RFFT instance structure
 * @return Status code
 */
rfft_status_t rfft_q15_init_8192(arm_rfft_instance_q15 *S);
#endif

/**
 * @brief Process real FFT on Q15 data.
 * @param[in]  S     Pointer to RFFT instance structure
 * @param[in]  pSrc  Pointer to input buffer (modified in-place)
 * @param[out] pDst  Pointer to output buffer
 */
void arm_rfft_q15(
    const arm_rfft_instance_q15 * S,
    q15_t * pSrc,
    q15_t * pDst);

/**
 * @brief Process complex FFT on Q15 data.
 * @param[in]     S               Pointer to CFFT instance structure
 * @param[in,out] p1              Pointer to complex data buffer (in-place)
 * @param[in]     ifftFlag        0=forward FFT, 1=inverse FFT
 * @param[in]     bitReverseFlag  0=disable bit reversal, 1=enable bit reversal
 */
void arm_cfft_q15(
    const arm_cfft_instance_q15 * S,
    q15_t * p1,
    uint8_t ifftFlag,
    uint8_t bitReverseFlag);

/**
 * @brief Bit reversal function for Q15 data.
 * @param[in,out] pSrc         Pointer to data buffer
 * @param[in]     bitRevLen    Bit reversal table length
 * @param[in]     pBitRevTable Pointer to bit reversal table
 */
void arm_bitreversal_16(
    uint16_t * pSrc,
    const uint16_t bitRevLen,
    const uint16_t * pBitRevTable);

/* ========================================================================= */
/* Helper Functions                                                          */
/* ========================================================================= */

/**
 * @brief Convert 16-bit ADC value to Q15 format.
 * @param[in] adc_value  ADC value (0-65535)
 * @return Q15 value (-32768 to 32767)
 * 
 * @note This maps ADC midpoint (32768) to Q15 zero (0).
 */
static inline q15_t adc_to_q15(uint16_t adc_value) {
    return (q15_t)(adc_value - 32768);
}

/**
 * @brief Convert Q15 value to floating point.
 * @param[in] q15_value  Q15 value
 * @return Floating point value (-1.0 to ~1.0)
 * 
 * @note Useful for verification and debugging.
 */
static inline float q15_to_float(q15_t q15_value) {
    return (float)q15_value / 32768.0f;
}

/**
 * @brief Convert floating point to Q15 value.
 * @param[in] float_value  Floating point value (-1.0 to 1.0)
 * @return Q15 value
 * 
 * @note Values outside [-1.0, 1.0] will be saturated.
 */
static inline q15_t float_to_q15(float float_value) {
    if (float_value >= 1.0f) return 32767;
    if (float_value <= -1.0f) return -32768;
    return (q15_t)(float_value * 32768.0f);
}

/* ========================================================================= */
/* DSP Intrinsics Compatibility                                              */
/* ========================================================================= */

#if defined (ARM_MATH_DSP)
/* DSP intrinsics are available - use CMSIS-Core definitions */
#include "cmsis_compiler.h"

/* Helper macros for reading/writing Q15 pairs */
#define read_q15x2(addr)        (*((q31_t *)(addr)))
#define read_q15x2_ia(addr)     (*((q31_t *)(addr))++)
#define read_q15x2_da(addr)     (*((q31_t *)(addr))--)
#define write_q15x2(addr, val)  (*((q31_t *)(addr)) = (val))
#define write_q15x2_ia(addr, val) (*((q31_t *)(addr))++ = (val))

#else
/* No DSP intrinsics - provide scalar fallbacks */
#define __SSAT(val, bits)       ((val) > ((1 << ((bits)-1)) - 1) ? ((1 << ((bits)-1)) - 1) : \
                                 (val) < (-(1 << ((bits)-1))) ? (-(1 << ((bits)-1))) : (val))

#define read_q15x2(addr)        (*((q31_t *)(addr)))
#define read_q15x2_ia(addr)     (*((q31_t *)(addr))++)
#define read_q15x2_da(addr)     (*((q31_t *)(addr))--)
#define write_q15x2(addr, val)  (*((q31_t *)(addr)) = (val))
#define write_q15x2_ia(addr, val) (*((q31_t *)(addr))++ = (val))

#endif /* ARM_MATH_DSP */

/* ========================================================================= */
/* External Table Declarations                                               */
/* ========================================================================= */

/* CFFT Twiddle Coefficients */
extern const q15_t twiddleCoef_2048_q15[3072];

#ifdef ENABLE_FFT_8K
extern const q15_t twiddleCoef_4096_q15[6144];
#endif

/* RFFT Real Coefficients */
extern const q15_t realCoefAQ15[8192];
extern const q15_t realCoefBQ15[8192];

/* Bit Reversal Tables */
extern const uint16_t armBitRevIndexTable_fixed_2048[];

#ifdef ENABLE_FFT_8K
extern const uint16_t armBitRevIndexTable_fixed_4096[];
#endif

/* Bit Reversal Table Lengths */
#define ARMBITREVINDEXTABLE_FIXED_2048_TABLE_LENGTH  1984

#ifdef ENABLE_FFT_8K
#define ARMBITREVINDEXTABLE_FIXED_4096_TABLE_LENGTH  4032
#endif

#ifdef __cplusplus
}
#endif

#endif /* RFFT_Q15_H */
```
